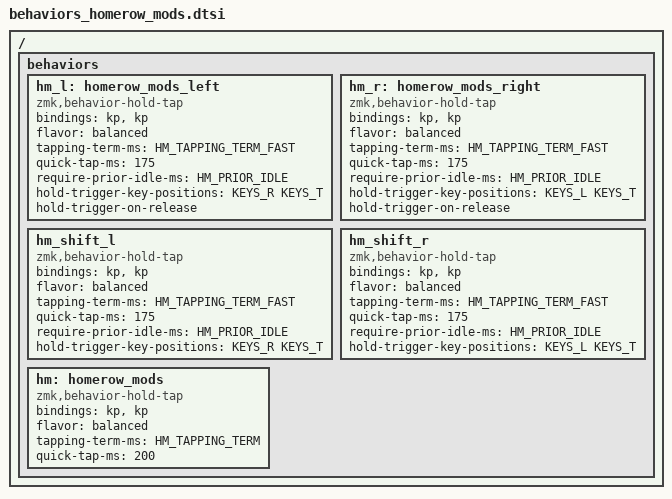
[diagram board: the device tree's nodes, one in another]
// Make sure settings.dtsi is included before this file

#define HM_TAPPING_TERM 300
#define HM_TAPPING_TERM_FAST 175
#define HM_PRIOR_IDLE 150

/ {

    behaviors {

        // Positional Homerow mods
        // Homerow mods that prevent accidental activations when rolling keys,
        // such as when typing `st` or `ne` on colemak-dh layouts or `as` on
        // qwerty.
        //
        // Works by only allowing a mod to activate within tapping-term if
        // it's on the opposite side of the keyboard or on the same side thumb
        // keys.

        // Further optimization using urob's timerless homerow mods method:
        // https://github.com/urob/zmk-config#timeless-homerow-mods
        hm_l: homerow_mods_left {
            compatible = "zmk,behavior-hold-tap";
            #binding-cells = <2>;
            bindings = <&kp>,  <&kp>;

            flavor = "balanced";

            // how long must a key be held to trigger hold behavior
            tapping-term-ms = <HM_TAPPING_TERM_FAST>;
 
            // sets threshold to press twice to always trigger the tap behavior (like to hold down backspace, can tap twice within this term)
            quick-tap-ms = <175>;                // repeat on tap-into-hold

            // like quick-tap-ms but works for any key pressed before it. Removes input delay, and is useful for HRM.
            require-prior-idle-ms = <HM_PRIOR_IDLE>;

            // pressing any of these keys before tapping-term-ms generates a tap
            hold-trigger-key-positions = <KEYS_R KEYS_T>;
            hold-trigger-on-release; // delay positional check until key-release
        };

        hm_r: homerow_mods_right {
            compatible = "zmk,behavior-hold-tap";
            #binding-cells = <2>;
            bindings = <&kp>, <&kp>;

            flavor = "balanced";
            tapping-term-ms = <HM_TAPPING_TERM_FAST>;
            quick-tap-ms = <175>;
            require-prior-idle-ms = <HM_PRIOR_IDLE>;

            hold-trigger-key-positions = <KEYS_L KEYS_T>;
            hold-trigger-on-release;
        };


        // Positional Homerow mods for shift
        // Use faster tapping term and disable some features that may
        // cause false negatives.
        hm_shift_l: hm_shift_l {
            compatible = "zmk,behavior-hold-tap";
            #binding-cells = <2>;
            bindings = <&kp>, <&kp>;

            flavor = "balanced";
            tapping-term-ms = <HM_TAPPING_TERM_FAST>;
            quick-tap-ms = <175>;
            require-prior-idle-ms = <HM_PRIOR_IDLE>;

            hold-trigger-key-positions = <KEYS_R KEYS_T>;
            // hold-trigger-on-release;
        };

        hm_shift_r: hm_shift_r {
            compatible = "zmk,behavior-hold-tap";
            #binding-cells = <2>;
            bindings = <&kp>, <&kp>;

            flavor = "balanced";
            tapping-term-ms = <HM_TAPPING_TERM_FAST>;
            quick-tap-ms = <175>;
            require-prior-idle-ms = <HM_PRIOR_IDLE>;

            hold-trigger-key-positions = <KEYS_L KEYS_T>;
            // hold-trigger-on-release;
        };

        /*
         * Non-Positional Homerow Mods
         * Used for &mm_grescm_gui behavior on left hand.
         *
         * Usage: &hm LSHFT T
         * Tap: T
         * Tap-Tap-Hold: Repeat T
         * Hold: LSHIFT
         */
        hm: homerow_mods {
            compatible = "zmk,behavior-hold-tap";
            #binding-cells = <2>;
            bindings = <&kp>, <&kp>;

            flavor = "balanced";
            tapping-term-ms = <HM_TAPPING_TERM>;
            quick-tap-ms = <200>;
        };

    };
};
